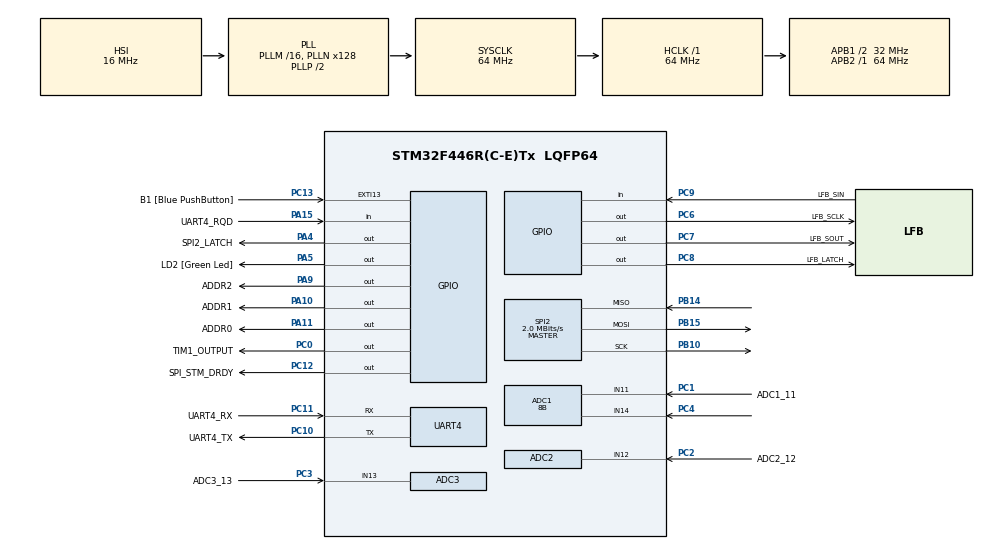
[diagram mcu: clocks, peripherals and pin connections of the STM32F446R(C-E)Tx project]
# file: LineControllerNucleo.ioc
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ADC1.Channel-0\#ChannelRegularConversion=ADC_CHANNEL_11
ADC1.ClockPrescaler=ADC_CLOCK_SYNC_PCLK_DIV8
ADC1.ContinuousConvMode=DISABLE
ADC1.DMAContinuousRequests=DISABLE
ADC1.DataAlign=ADC_DATAALIGN_RIGHT
ADC1.DiscontinuousConvMode=DISABLE
ADC1.EOCSelection=ADC_EOC_SINGLE_CONV
ADC1.EnableAnalogWatchDog=false
ADC1.ExternalTrigConv=ADC_SOFTWARE_START
ADC1.ExternalTrigConvEdge=ADC_EXTERNALTRIGCONVEDGE_NONE
ADC1.InjNumberOfConversion=0
ADC1.NbrOfConversion=1
ADC1.NbrOfConversionFlag=1
ADC1.Rank-0\#ChannelRegularConversion=1
ADC1.Resolution=ADC_RESOLUTION_8B
ADC1.SamplingTime-0\#ChannelRegularConversion=ADC_SAMPLETIME_3CYCLES
ADC1.ScanConvMode=DISABLE
ADC1.master=1
ADC2.Channel-0\#ChannelRegularConversion=ADC_CHANNEL_12
ADC2.ClockPrescaler=ADC_CLOCK_SYNC_PCLK_DIV8
ADC2.NbrOfConversionFlag=1
ADC2.Rank-0\#ChannelRegularConversion=1
ADC2.Resolution=ADC_RESOLUTION_8B
ADC2.SamplingTime-0\#ChannelRegularConversion=ADC_SAMPLETIME_3CYCLES
ADC3.Channel-4\#ChannelRegularConversion=ADC_CHANNEL_13
ADC3.ClockPrescaler=ADC_CLOCK_SYNC_PCLK_DIV8
ADC3.NbrOfConversionFlag=1
ADC3.Rank-4\#ChannelRegularConversion=1
ADC3.Resolution=ADC_RESOLUTION_8B
ADC3.SamplingTime-4\#ChannelRegularConversion=ADC_SAMPLETIME_3CYCLES
Mcu.Family=STM32F4
Mcu.Name=STM32F446R(C-E)Tx
Mcu.Package=LQFP64
NVIC.ADC_IRQn=true\:0\:0\:false\:false\:true\:true
NVIC.PriorityGroup=NVIC_PRIORITYGROUP_0
NVIC.SPI2_IRQn=true\:0\:0\:false\:false\:true\:true
NVIC.TIM1_BRK_TIM9_IRQn=true\:0\:0\:false\:false\:true\:true
NVIC.TIM1_CC_IRQn=true\:0\:0\:false\:false\:true\:true
NVIC.TIM1_TRG_COM_TIM11_IRQn=true\:0\:0\:false\:false\:true\:true
NVIC.TIM1_UP_TIM10_IRQn=true\:0\:0\:false\:false\:true\:true
NVIC.UART4_IRQn=true\:0\:0\:false\:false\:true\:true
PA10.GPIO_Label=ADDR1
PA10.GPIO_Speed=GPIO_SPEED_FREQ_VERY_HIGH
PA10.Signal=GPIO_Output
PA11.GPIO_Label=ADDR0
PA11.GPIO_Speed=GPIO_SPEED_FREQ_VERY_HIGH
PA11.Signal=GPIO_Output
PA13.GPIO_Label=TMS
PA13.Signal=SYS_JTMS-SWDIO
PA14.GPIO_Label=TCK
PA14.Signal=SYS_JTCK-SWCLK
PA15.GPIO_Label=UART4_RQD
PA15.Signal=GPIO_Input
PA4.GPIO_Label=SPI2_LATCH
PA4.Signal=GPIO_Output
PA5.GPIO_Label=LD2 [Green Led]
PA5.Signal=GPIO_Output
PA9.GPIO_Label=ADDR2
PA9.GPIO_Speed=GPIO_SPEED_FREQ_VERY_HIGH
PA9.Signal=GPIO_Output
PB10.Mode=Full_Duplex_Master
PB10.Signal=SPI2_SCK
PB14.Mode=Full_Duplex_Master
PB14.Signal=SPI2_MISO
PB15.Mode=Full_Duplex_Master
PB15.Signal=SPI2_MOSI
PB3.GPIO_Label=SWO
PB3.Signal=SYS_JTDO-SWO
PC0.GPIO_Label=TIM1_OUTPUT
PC0.Signal=GPIO_Output
PC1.GPIO_Label=ADC1_11
PC1.Signal=ADCx_IN11
PC10.GPIO_Label=UART4_TX
PC10.Mode=Asynchronous
PC10.Signal=UART4_TX
PC11.GPIO_Label=UART4_RX
PC11.Mode=Asynchronous
PC11.Signal=UART4_RX
PC12.GPIO_Label=SPI_STM_DRDY
PC12.Signal=GPIO_Output
PC13.GPIO_Label=B1 [Blue PushButton]
PC13.GPIO_ModeDefaultEXTI=GPIO_MODE_IT_FALLING
PC13.Signal=GPXTI13
PC14-OSC32_IN.Signal=RCC_OSC32_IN
PC15-OSC32_OUT.Signal=RCC_OSC32_OUT
PC2.GPIO_Label=ADC2_12
PC2.Signal=ADCx_IN12
PC3.GPIO_Label=ADC3_13
PC3.Signal=ADCx_IN13
PC4.Signal=ADCx_IN14
PC6.GPIO_Label=LFB_SCLK
PC6.Signal=GPIO_Output
PC7.GPIO_Label=LFB_SOUT
PC7.Signal=GPIO_Output
PC8.GPIO_Label=LFB_LATCH
PC8.Signal=GPIO_Output
PC9.GPIO_Label=LFB_SIN
PC9.Signal=GPIO_Input
PH0-OSC_IN.Signal=RCC_OSC_IN
PH1-OSC_OUT.Signal=RCC_OSC_OUT
ProjectManager.HeapSize=0x200
ProjectManager.StackSize=0x400
ProjectManager.TargetToolchain=SW4STM32
RCC.AHBFreq_Value=64000000
RCC.APB1CLKDivider=RCC_HCLK_DIV2
RCC.APB1Freq_Value=32000000
RCC.APB1TimFreq_Value=64000000
RCC.APB2Freq_Value=64000000
RCC.APB2TimFreq_Value=64000000
RCC.CortexFreq_Value=64000000
RCC.FLatency-AdvancedSettings=FLASH_LATENCY_2
RCC.HCLKFreq_Value=64000000
RCC.HSE_VALUE=8000000
RCC.HSI_VALUE=16000000
RCC.LSE_VALUE=32768
RCC.PLLN=128
RCC.SYSCLKFreq_VALUE=64000000
RCC.SYSCLKSource=RCC_SYSCLKSOURCE_PLLCLK
RCC.USBFreq_Value=64000000
RCC.VCOOutputFreq_Value=128000000
SH.ADCx_IN11.0=ADC1_IN11,IN11
SH.ADCx_IN12.0=ADC2_IN12,IN12
SH.ADCx_IN13.0=ADC1_IN13
SH.ADCx_IN13.1=ADC3_IN13,IN13
SH.ADCx_IN14.0=ADC1_IN14,IN14
SPI2.BaudRatePrescaler=SPI_BAUDRATEPRESCALER_16
SPI2.CalculateBaudRate=2.0 MBits/s
SPI2.Direction=SPI_DIRECTION_2LINES
SPI2.Mode=SPI_MODE_MASTER
SPI2.VirtualType=VM_MASTER
TIM1.Period=0
TIM1.Prescaler=0
UART4.VirtualMode=Asynchronous
VP_TIM1_VS_ClockSourceINT.Mode=Internal
VP_TIM1_VS_OPM.Mode=OPM_bit
board=NUCLEO-F446RE

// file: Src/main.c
/**
  ******************************************************************************
  * File Name          : main.c
  * Description        : Main program body
  ******************************************************************************
  ** This notice applies to any and all portions of this file
  * that are not between comment pairs USER CODE BEGIN and
  * USER CODE END. Other portions of this file, whether
  * inserted by the user or by software development tools
  * are owned by their respective copyright owners.
  *
  * COPYRIGHT(c) 2017 STMicroelectronics
  *
  * Redistribution and use in source and binary forms, with or without modification,
  * are permitted provided that the following conditions are met:
  *   1. Redistributions of source code must retain the above copyright notice,
  *      this list of conditions and the following disclaimer.
  *   2. Redistributions in binary form must reproduce the above copyright notice,
  *      this list of conditions and the following disclaimer in the documentation
  *      and/or other materials provided with the distribution.
  *   3. Neither the name of STMicroelectronics nor the names of its contributors
  *      may be used to endorse or promote products derived from this software
  *      without specific prior written permission.
  *
  * THIS SOFTWARE IS PROVIDED BY THE COPYRIGHT HOLDERS AND CONTRIBUTORS "AS IS"
  * AND ANY EXPRESS OR IMPLIED WARRANTIES, INCLUDING, BUT NOT LIMITED TO, THE
  * IMPLIED WARRANTIES OF MERCHANTABILITY AND FITNESS FOR A PARTICULAR PURPOSE ARE
  * DISCLAIMED. IN NO EVENT SHALL THE COPYRIGHT HOLDER OR CONTRIBUTORS BE LIABLE
  * FOR ANY DIRECT, INDIRECT, INCIDENTAL, SPECIAL, EXEMPLARY, OR CONSEQUENTIAL
  * DAMAGES (INCLUDING, BUT NOT LIMITED TO, PROCUREMENT OF SUBSTITUTE GOODS OR
  * SERVICES; LOSS OF USE, DATA, OR PROFITS; OR BUSINESS INTERRUPTION) HOWEVER
  * CAUSED AND ON ANY THEORY OF LIABILITY, WHETHER IN CONTRACT, STRICT LIABILITY,
  * OR TORT (INCLUDING NEGLIGENCE OR OTHERWISE) ARISING IN ANY WAY OUT OF THE USE
  * OF THIS SOFTWARE, EVEN IF ADVISED OF THE POSSIBILITY OF SUCH DAMAGE.
  *
  ******************************************************************************
  */
#include "main.h"
#include "stm32f4xx_hal.h"

/* USER CODE BEGIN Includes */

#include "lst_lineControllerNucleo.h"

/* USER CODE END Includes */

ADC_HandleTypeDef hadc1;
ADC_HandleTypeDef hadc2;
ADC_HandleTypeDef hadc3;

SPI_HandleTypeDef hspi2;

TIM_HandleTypeDef htim1;

UART_HandleTypeDef huart4;

/* USER CODE BEGIN PV */
/* Private variables ---------------------------------------------------------*/

/* USER CODE END PV */

void SystemClock_Config(void);
static void MX_GPIO_Init(void);
static void MX_TIM1_Init(void);
static void MX_ADC1_Init(void);
static void MX_ADC2_Init(void);
static void MX_SPI2_Init(void);
static void MX_ADC3_Init(void);
static void MX_UART4_Init(void);

/* USER CODE BEGIN PFP */
/* Private function prototypes -----------------------------------------------*/

/* USER CODE END PFP */

int main(void)
{

  /* MCU Configuration----------------------------------------------------------*/

  /* Reset of all peripherals, Initializes the Flash interface and the Systick. */
  HAL_Init();

  /* Configure the system clock */
  SystemClock_Config();

  /* Initialize all configured peripherals */
  MX_GPIO_Init();
  MX_TIM1_Init();
  MX_ADC1_Init();
  MX_ADC2_Init();
  MX_SPI2_Init();
  MX_ADC3_Init();
  MX_UART4_Init();

  /* Infinite loop */
  while (1)
  {

  /* USER CODE BEGIN 3 */

	  lst_entry_point();

  }
  /* USER CODE END 3 */

}

/** System Clock Configuration
*/
void SystemClock_Config(void)
{

  RCC_OscInitTypeDef RCC_OscInitStruct;
  RCC_ClkInitTypeDef RCC_ClkInitStruct;

    /**Configure the main internal regulator output voltage
    */
  __HAL_RCC_PWR_CLK_ENABLE();

  __HAL_PWR_VOLTAGESCALING_CONFIG(PWR_REGULATOR_VOLTAGE_SCALE3);

    /**Initializes the CPU, AHB and APB busses clocks
    */
  RCC_OscInitStruct.OscillatorType = RCC_OSCILLATORTYPE_HSI;
  RCC_OscInitStruct.HSIState = RCC_HSI_ON;
  RCC_OscInitStruct.HSICalibrationValue = 16;
  RCC_OscInitStruct.PLL.PLLState = RCC_PLL_ON;
  RCC_OscInitStruct.PLL.PLLSource = RCC_PLLSOURCE_HSI;
  RCC_OscInitStruct.PLL.PLLM = 16;
  RCC_OscInitStruct.PLL.PLLN = 128;
  RCC_OscInitStruct.PLL.PLLP = RCC_PLLP_DIV2;
  RCC_OscInitStruct.PLL.PLLQ = 2;
  RCC_OscInitStruct.PLL.PLLR = 2;
  if (HAL_RCC_OscConfig(&RCC_OscInitStruct) != HAL_OK)
  {
    _Error_Handler(__FILE__, __LINE__);
  }

    /**Initializes the CPU, AHB and APB busses clocks
    */
  RCC_ClkInitStruct.ClockType = RCC_CLOCKTYPE_HCLK|RCC_CLOCKTYPE_SYSCLK
                              |RCC_CLOCKTYPE_PCLK1|RCC_CLOCKTYPE_PCLK2;
  RCC_ClkInitStruct.SYSCLKSource = RCC_SYSCLKSOURCE_PLLCLK;
  RCC_ClkInitStruct.AHBCLKDivider = RCC_SYSCLK_DIV1;
  RCC_ClkInitStruct.APB1CLKDivider = RCC_HCLK_DIV2;
  RCC_ClkInitStruct.APB2CLKDivider = RCC_HCLK_DIV1;

  if (HAL_RCC_ClockConfig(&RCC_ClkInitStruct, FLASH_LATENCY_2) != HAL_OK)
  {
    _Error_Handler(__FILE__, __LINE__);
  }

    /**Configure the Systick interrupt time
    */
  HAL_SYSTICK_Config(HAL_RCC_GetHCLKFreq()/1000);

    /**Configure the Systick
    */
  HAL_SYSTICK_CLKSourceConfig(SYSTICK_CLKSOURCE_HCLK);

  /* SysTick_IRQn interrupt configuration */
  HAL_NVIC_SetPriority(SysTick_IRQn, 0, 0);
}

/* ADC1 init function */
static void MX_ADC1_Init(void)
{

  ADC_ChannelConfTypeDef sConfig;

    /**Configure the global features of the ADC (Clock, Resolution, Data Alignment and number of conversion)
    */
  hadc1.Instance = ADC1;
  hadc1.Init.ClockPrescaler = ADC_CLOCK_SYNC_PCLK_DIV8;
  hadc1.Init.Resolution = ADC_RESOLUTION_8B;
  hadc1.Init.ScanConvMode = DISABLE;
  hadc1.Init.ContinuousConvMode = DISABLE;
  hadc1.Init.DiscontinuousConvMode = DISABLE;
  hadc1.Init.ExternalTrigConvEdge = ADC_EXTERNALTRIGCONVEDGE_NONE;
  hadc1.Init.ExternalTrigConv = ADC_SOFTWARE_START;
  hadc1.Init.DataAlign = ADC_DATAALIGN_RIGHT;
  hadc1.Init.NbrOfConversion = 1;
  hadc1.Init.DMAContinuousRequests = DISABLE;
  hadc1.Init.EOCSelection = ADC_EOC_SINGLE_CONV;
  if (HAL_ADC_Init(&hadc1) != HAL_OK)
  {
    _Error_Handler(__FILE__, __LINE__);
  }

    /**Configure for the selected ADC regular channel its corresponding rank in the sequencer and its sample time.
    */
  sConfig.Channel = ADC_CHANNEL_11;
  sConfig.Rank = 1;
  sConfig.SamplingTime = ADC_SAMPLETIME_3CYCLES;
  if (HAL_ADC_ConfigChannel(&hadc1, &sConfig) != HAL_OK)
  {
    _Error_Handler(__FILE__, __LINE__);
  }

}

/* ADC2 init function */
static void MX_ADC2_Init(void)
{

  ADC_ChannelConfTypeDef sConfig;

    /**Configure the global features of the ADC (Clock, Resolution, Data Alignment and number of conversion)
    */
  hadc2.Instance = ADC2;
  hadc2.Init.ClockPrescaler = ADC_CLOCK_SYNC_PCLK_DIV8;
  hadc2.Init.Resolution = ADC_RESOLUTION_8B;
  hadc2.Init.ScanConvMode = DISABLE;
  hadc2.Init.ContinuousConvMode = DISABLE;
  hadc2.Init.DiscontinuousConvMode = DISABLE;
  hadc2.Init.ExternalTrigConvEdge = ADC_EXTERNALTRIGCONVEDGE_NONE;
  hadc2.Init.ExternalTrigConv = ADC_SOFTWARE_START;
  hadc2.Init.DataAlign = ADC_DATAALIGN_RIGHT;
  hadc2.Init.NbrOfConversion = 1;
  hadc2.Init.DMAContinuousRequests = DISABLE;
  hadc2.Init.EOCSelection = ADC_EOC_SINGLE_CONV;
  if (HAL_ADC_Init(&hadc2) != HAL_OK)
  {
    _Error_Handler(__FILE__, __LINE__);
  }

    /**Configure for the selected ADC regular channel its corresponding rank in the sequencer and its sample time.
    */
  sConfig.Channel = ADC_CHANNEL_12;
  sConfig.Rank = 1;
  sConfig.SamplingTime = ADC_SAMPLETIME_3CYCLES;
  if (HAL_ADC_ConfigChannel(&hadc2, &sConfig) != HAL_OK)
  {
    _Error_Handler(__FILE__, __LINE__);
  }

}

/* ADC3 init function */
static void MX_ADC3_Init(void)
{

  ADC_ChannelConfTypeDef sConfig;

    /**Configure the global features of the ADC (Clock, Resolution, Data Alignment and number of conversion)
    */
  hadc3.Instance = ADC3;
  hadc3.Init.ClockPrescaler = ADC_CLOCK_SYNC_PCLK_DIV8;
  hadc3.Init.Resolution = ADC_RESOLUTION_8B;
  hadc3.Init.ScanConvMode = DISABLE;
  hadc3.Init.ContinuousConvMode = DISABLE;
  hadc3.Init.DiscontinuousConvMode = DISABLE;
  hadc3.Init.ExternalTrigConvEdge = ADC_EXTERNALTRIGCONVEDGE_NONE;
  hadc3.Init.ExternalTrigConv = ADC_SOFTWARE_START;
  hadc3.Init.DataAlign = ADC_DATAALIGN_RIGHT;
  hadc3.Init.NbrOfConversion = 1;
  hadc3.Init.DMAContinuousRequests = DISABLE;
  hadc3.Init.EOCSelection = ADC_EOC_SINGLE_CONV;
  if (HAL_ADC_Init(&hadc3) != HAL_OK)
  {
    _Error_Handler(__FILE__, __LINE__);
  }

    /**Configure for the selected ADC regular channel its corresponding rank in the sequencer and its sample time.
    */
  sConfig.Channel = ADC_CHANNEL_13;
  sConfig.Rank = 1;
  sConfig.SamplingTime = ADC_SAMPLETIME_3CYCLES;
  if (HAL_ADC_ConfigChannel(&hadc3, &sConfig) != HAL_OK)
  {
    _Error_Handler(__FILE__, __LINE__);
  }

}

/* SPI2 init function */
static void MX_SPI2_Init(void)
{

  /* SPI2 parameter configuration*/
  hspi2.Instance = SPI2;
  hspi2.Init.Mode = SPI_MODE_MASTER;
  hspi2.Init.Direction = SPI_DIRECTION_2LINES;
  hspi2.Init.DataSize = SPI_DATASIZE_8BIT;
  hspi2.Init.CLKPolarity = SPI_POLARITY_LOW;
  hspi2.Init.CLKPhase = SPI_PHASE_1EDGE;
  hspi2.Init.NSS = SPI_NSS_SOFT;
  hspi2.Init.BaudRatePrescaler = SPI_BAUDRATEPRESCALER_16;
  hspi2.Init.FirstBit = SPI_FIRSTBIT_MSB;
  hspi2.Init.TIMode = SPI_TIMODE_DISABLE;
  hspi2.Init.CRCCalculation = SPI_CRCCALCULATION_DISABLE;
  hspi2.Init.CRCPolynomial = 10;
  if (HAL_SPI_Init(&hspi2) != HAL_OK)
  {
    _Error_Handler(__FILE__, __LINE__);
  }

}

/* TIM1 init function */
static void MX_TIM1_Init(void)
{

  TIM_ClockConfigTypeDef sClockSourceConfig;
  TIM_MasterConfigTypeDef sMasterConfig;

  htim1.Instance = TIM1;
  htim1.Init.Prescaler = 0;
  htim1.Init.CounterMode = TIM_COUNTERMODE_UP;
  htim1.Init.Period = 0;
  htim1.Init.ClockDivision = TIM_CLOCKDIVISION_DIV1;
  htim1.Init.RepetitionCounter = 0;
  if (HAL_TIM_Base_Init(&htim1) != HAL_OK)
  {
    _Error_Handler(__FILE__, __LINE__);
  }

  sClockSourceConfig.ClockSource = TIM_CLOCKSOURCE_INTERNAL;
  if (HAL_TIM_ConfigClockSource(&htim1, &sClockSourceConfig) != HAL_OK)
  {
    _Error_Handler(__FILE__, __LINE__);
  }

  if (HAL_TIM_OnePulse_Init(&htim1, TIM_OPMODE_SINGLE) != HAL_OK)
  {
    _Error_Handler(__FILE__, __LINE__);
  }

  sMasterConfig.MasterOutputTrigger = TIM_TRGO_RESET;
  sMasterConfig.MasterSlaveMode = TIM_MASTERSLAVEMODE_DISABLE;
  if (HAL_TIMEx_MasterConfigSynchronization(&htim1, &sMasterConfig) != HAL_OK)
  {
    _Error_Handler(__FILE__, __LINE__);
  }

}

/* UART4 init function */
static void MX_UART4_Init(void)
{

  huart4.Instance = UART4;
  huart4.Init.BaudRate = 115200;
  huart4.Init.WordLength = UART_WORDLENGTH_8B;
  huart4.Init.StopBits = UART_STOPBITS_1;
  huart4.Init.Parity = UART_PARITY_NONE;
  huart4.Init.Mode = UART_MODE_TX_RX;
  huart4.Init.HwFlowCtl = UART_HWCONTROL_NONE;
  huart4.Init.OverSampling = UART_OVERSAMPLING_16;
  if (HAL_UART_Init(&huart4) != HAL_OK)
  {
    _Error_Handler(__FILE__, __LINE__);
  }

}

/** Configure pins as
        * Analog
        * Input
        * Output
        * EVENT_OUT
        * EXTI
*/
static void MX_GPIO_Init(void)
{

  GPIO_InitTypeDef GPIO_InitStruct;

  /* GPIO Ports Clock Enable */
  __HAL_RCC_GPIOC_CLK_ENABLE();
  __HAL_RCC_GPIOH_CLK_ENABLE();
  __HAL_RCC_GPIOA_CLK_ENABLE();
  __HAL_RCC_GPIOB_CLK_ENABLE();

  /*Configure GPIO pin Output Level */
  HAL_GPIO_WritePin(GPIOC, TIM1_OUTPUT_Pin|LFB_SCLK_Pin|LFB_SOUT_Pin|LFB_LATCH_Pin
                          |SPI_STM_DRDY_Pin, GPIO_PIN_RESET);

  /*Configure GPIO pin Output Level */
  HAL_GPIO_WritePin(GPIOA, SPI2_LATCH_Pin|LD2_Pin|ADDR2_Pin|ADDR1_Pin
                          |ADDR0_Pin, GPIO_PIN_RESET);

  /*Configure GPIO pin : B1_Pin */
  GPIO_InitStruct.Pin = B1_Pin;
  GPIO_InitStruct.Mode = GPIO_MODE_IT_FALLING;
  GPIO_InitStruct.Pull = GPIO_NOPULL;
  HAL_GPIO_Init(B1_GPIO_Port, &GPIO_InitStruct);

  /*Configure GPIO pins : TIM1_OUTPUT_Pin LFB_SCLK_Pin LFB_SOUT_Pin LFB_LATCH_Pin
                           SPI_STM_DRDY_Pin */
  GPIO_InitStruct.Pin = TIM1_OUTPUT_Pin|LFB_SCLK_Pin|LFB_SOUT_Pin|LFB_LATCH_Pin
                          |SPI_STM_DRDY_Pin;
  GPIO_InitStruct.Mode = GPIO_MODE_OUTPUT_PP;
  GPIO_InitStruct.Pull = GPIO_NOPULL;
  GPIO_InitStruct.Speed = GPIO_SPEED_FREQ_LOW;
  HAL_GPIO_Init(GPIOC, &GPIO_InitStruct);

  /*Configure GPIO pins : SPI2_LATCH_Pin LD2_Pin */
  GPIO_InitStruct.Pin = SPI2_LATCH_Pin|LD2_Pin;
  GPIO_InitStruct.Mode = GPIO_MODE_OUTPUT_PP;
  GPIO_InitStruct.Pull = GPIO_NOPULL;
  GPIO_InitStruct.Speed = GPIO_SPEED_FREQ_LOW;
  HAL_GPIO_Init(GPIOA, &GPIO_InitStruct);

  /*Configure GPIO pin : LFB_SIN_Pin */
  GPIO_InitStruct.Pin = LFB_SIN_Pin;
  GPIO_InitStruct.Mode = GPIO_MODE_INPUT;
  GPIO_InitStruct.Pull = GPIO_NOPULL;
  HAL_GPIO_Init(LFB_SIN_GPIO_Port, &GPIO_InitStruct);

  /*Configure GPIO pins : ADDR2_Pin ADDR1_Pin ADDR0_Pin */
  GPIO_InitStruct.Pin = ADDR2_Pin|ADDR1_Pin|ADDR0_Pin;
  GPIO_InitStruct.Mode = GPIO_MODE_OUTPUT_PP;
  GPIO_InitStruct.Pull = GPIO_NOPULL;
  GPIO_InitStruct.Speed = GPIO_SPEED_FREQ_VERY_HIGH;
  HAL_GPIO_Init(GPIOA, &GPIO_InitStruct);

  /*Configure GPIO pin : UART4_RQD_Pin */
  GPIO_InitStruct.Pin = UART4_RQD_Pin;
  GPIO_InitStruct.Mode = GPIO_MODE_INPUT;
  GPIO_InitStruct.Pull = GPIO_NOPULL;
  HAL_GPIO_Init(UART4_RQD_GPIO_Port, &GPIO_InitStruct);

}

void _Error_Handler(char * file, int line)
{
  while(1)
  {
  }
}

/************************ (C) COPYRIGHT STMicroelectronics *****END OF FILE****/
